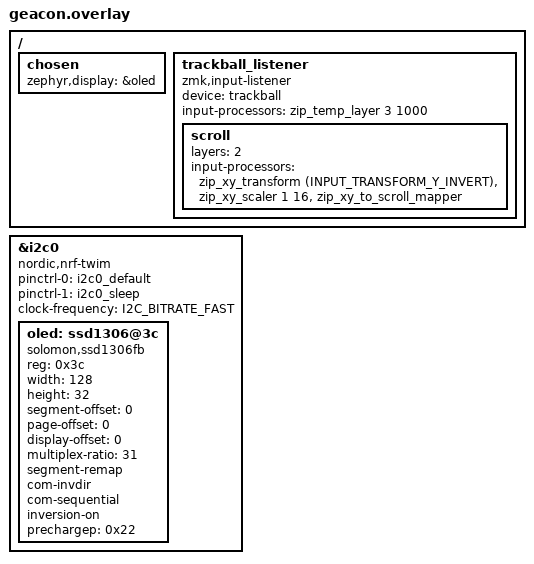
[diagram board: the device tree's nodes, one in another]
#include <dt-bindings/zmk/bt.h>
#include <input/processors.dtsi>
#include <dt-bindings/zmk/input_transform.h>
#include "geacon_pinctrl.dtsi"
#include "geacon.dtsi"

/ {
    chosen {
        zephyr,display = &oled;
    };
};


&i2c0 {
    compatible = "nordic,nrf-twim"; // I2C controller instead of generic
	  status = "okay";  // Re-enable I2C0

    pinctrl-0 = <&i2c0_default>;
    pinctrl-1 = <&i2c0_sleep>;
    pinctrl-names = "default", "sleep";
    clock-frequency = <I2C_BITRATE_FAST>;

    oled: ssd1306@3c {
        compatible = "solomon,ssd1306fb";
        reg = <0x3c>;
        width = <128>;
        height = <32>;
        segment-offset = <0>;
        page-offset = <0>;
        display-offset = <0>;
        multiplex-ratio = <31>;
        segment-remap;
        com-invdir;
        com-sequential;
        inversion-on;
        prechargep = <0x22>;
    };
};
  
/ {
  trackball_listener {
    status = "okay";
    compatible = "zmk,input-listener";
    device = <&trackball>;
    input-processors = <&zip_temp_layer 3 1000>;
    scroll {
      layers = <2>;
      input-processors = <&zip_xy_transform (INPUT_TRANSFORM_Y_INVERT)>, <&zip_xy_scaler 1 16>, <&zip_xy_to_scroll_mapper>;
    };

  };
};
